# R7FA4L1BD register map
Vendor: Renesas Electronics Corporation; Series: RA4; File version: 0.90.02
CPU: CM33 r0p4, little endian, MPU, FPU, VTOR, 4 interrupt priority bits, 96 interrupts
Registers are 32-bit, read-write, reset 0x0 unless marked. A register's access mark holds for its fields unless they carry their own. Offsets are from the block's base; [hi:lo] are bit positions; {n}, {i} and the like mark numbered series; 'fields as' and 'values as' point back to an identical list.

## BUS — Bus Control
Base 0x40003000
0x1100 BUSSCNTFHBIU 16-bit — Slave Bus Control Register
  [1:0] ARBS — Arbitration Select for two masters
    0=DMAC/DTC > CPU; 1=DMAC/DTC ↔ CPU; 2=Setting prohibited; 3=Setting prohibited
0x1104 BUSSCNTFLBIU 16-bit — Slave Bus Control Register
  fields as BUSSCNTFHBIU
0x1110 BUSSCNTS0BIU 16-bit — Slave Bus Control Register
  fields as BUSSCNTFHBIU
0x1120 BUSSCNTPSBIU 16-bit — Slave Bus Control Register
  [0] ARBS — Arbitration Select for two masters
    0=DMAC/DTC > CPU; 1=DMAC/DTC ↔ CPU
0x1130 BUSSCNTPLBIU 16-bit — Slave Bus Control Register
  fields as BUSSCNTPSBIU
0x1134 BUSSCNTPHBIU 16-bit — Slave Bus Control Register
  fields as BUSSCNTPSBIU
0x1140 BUSSCNTEQBIU 16-bit — Slave Bus Control Register
  fields as BUSSCNTFHBIU
{0x17F0+0x10*i} BUS{i}ERRADD (i=1..3) ro — BUS Error Address Register
  [31:0] BERAD — Bus Error Address
{0x17F4+0x10*i} BUS{i}ERRRW (i=1..3) 8-bit — BUS Error Read Write Register
  [0] RWSTAT ro — Error Access Read/Write Status
    0=Read access; 1=Write access
{0x18F0+0x10*i} BTZF{i}ERRADD (i=1..3) ro — BUS TZF Error Address Register
  [31:0] BTZFERAD — Bus TrustZone Filter Error Address
{0x18F4+0x10*i} BTZF{i}ERRRW (i=1..3) 8-bit — BUS TZF Error Read Write Register
  [0] TRWSTAT ro — TrustZone Filter Error Access Read/Write Status
    0=Read access; 1=Write access
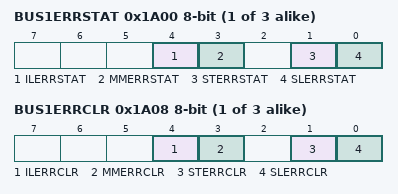
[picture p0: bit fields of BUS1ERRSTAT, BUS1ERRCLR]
{0x19F0+0x10*i} BUS{i}ERRSTAT (i=1..3) 8-bit ro — BUS Error Status Register {i}
  [all] fields
    0=No error occurred; 1=Error occurred
  [4] ILERRSTAT — Illegal Address Access Error Status
  [3] MMERRSTAT — Master MPU Error Status
  [1] STERRSTAT — Slave TrustZone Filter Error Status
  [0] SLERRSTAT — Slave Bus Error Status
{0x19F8+0x10*i} BUS{i}ERRCLR (i=1..3) 8-bit — BUS Error Clear Register {i}
  [4] ILERRCLR — Illegal Address Access Error Clear
  [3] MMERRCLR — Master MPU Error Clear
  [1] STERRCLR — Slave TrustZone Filter Error Clear
  [0] SLERRCLR — Slave Bus Error Clear
0x1A24 DMACDTCERRSTAT 8-bit ro — DMAC/DTC Error Status Register
  [0] MTERRSTAT — Master TrustZone Filter Error Status
    0=No error occurred; 1=Error occurred
0x1A2C DMACDTCERRCLR 8-bit — DMAC/DTC Error Clear Register
  [0] MTERRCLR — Master TrustZone filter Error Clear

## DMA — DMAC Module Activation
Base 0x40005200
0x00 DMAST 8-bit — DMA Module Activation Register
  [0] DMST — DMAC Operation Enable
    0=DMAC activation is disabled; 1=DMAC activation is enabled
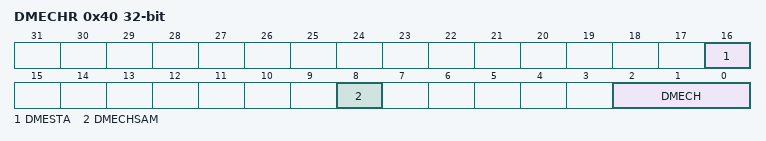
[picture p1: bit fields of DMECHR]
0x40 DMECHR — DMAC Error Channel Register
  [16] DMESTA — DMAC Error Status
    0=No DMA transfer error occurred; 1=DMA transfer error occurred
  [8] DMECHSAM ro — DMAC Error channel Security Attribution Monitor
    0=Secure channel; 1=Non-secure channel
  [2:0] DMECH ro — DMAC Error channel

## DTC — Data Transfer Controller
Base 0x40005400
0x00 DTCCR 8-bit reset 0x8 — DTC Control Register
  [4] RRS — DTC Transfer Information Read Skip Enable
    0=Transfer information read is not skipped; 1=Transfer information read is skipped when vector numbers match
0x04 DTCVBR — DTC Vector Base Register
0x0C DTCST 8-bit — DTC Module Start Register
  [0] DTCST — DTC Module Start
    0=DTC module stopped; 1=DTC module started
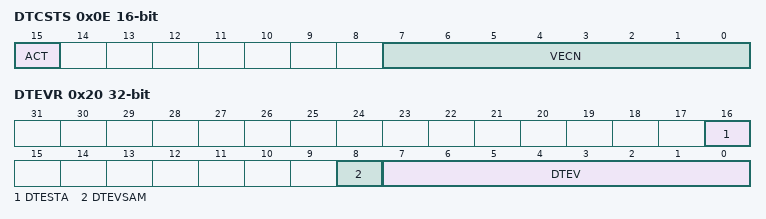
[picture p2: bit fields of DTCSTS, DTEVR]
0x0E DTCSTS 16-bit ro — DTC Status Register
  [15] ACT — DTC Active Flag
    0=DTC transfer operation is not in progress; 1=DTC transfer operation is in progress
  [7:0] VECN — DTC-Activating Vector Number Monitoring
0x10 DTCCR_SEC 8-bit reset 0x8 — DTC Control Register for Secure Region
  [4] RRS — DTC Transfer Information Read Skip Enable for Secure
    values as DTCCR.RRS
0x14 DTCVBR_SEC — DTC Vector Base Register for Secure Region
0x20 DTEVR — DTC Error Vector Register
  [16] DTESTA — DTC Error Status Flag
    0=No DTC transfer error occurred; 1=DTC transfer error occurred
  [8] DTEVSAM ro — DTC Error Vector Number SA Monitor
    0=Secure vector number; 1=Non-Secure vector number
  [7:0] DTEV ro — DTC Error Vector Number

## Notices in the file
This software is supplied by Renesas Electronics Corporation and is only intended for
use with Renesas products. No other uses are authorized. This software is owned by
Renesas Electronics Corporation and is protected under all applicable laws, including
copyright laws.
THIS SOFTWARE IS PROVIDED "AS IS" AND RENESAS MAKES NO WARRANTIES REGARDING
THIS SOFTWARE, WHETHER EXPRESS, IMPLIED OR STATUTORY, INCLUDING BUT NOT LIMITED TO
WARRANTIES OF MERCHANTABILITY, FITNESS FOR A PARTICULAR PURPOSE AND NON-INFRINGEMENT.
ALL SUCH WARRANTIES ARE EXPRESSLY DISCLAIMED. TO THE MAXIMUM EXTENT PERMITTED NOT
PROHIBITED BY LAW, NEITHER RENESAS ELECTRONICS CORPORATION NOR ANY OF ITS AFFILIATED
COMPANIES SHALL BE LIABLE FOR ANY DIRECT, INDIRECT, SPECIAL, INCIDENTAL OR CONSEQUENTIAL
DAMAGES FOR ANY REASON RELATED TO THIS SOFTWARE, EVEN IF RENESAS OR ITS AFFILIATES HAVE
BEEN ADVISED OF THE POSSIBILITY OF SUCH DAMAGES.
Renesas reserves the right, without notice, to make changes to this software and to
discontinue the availability of this software. By using this software, you agree to
the additional terms and conditions found by accessing the following link:
http://www.renesas.com/disclaimer
